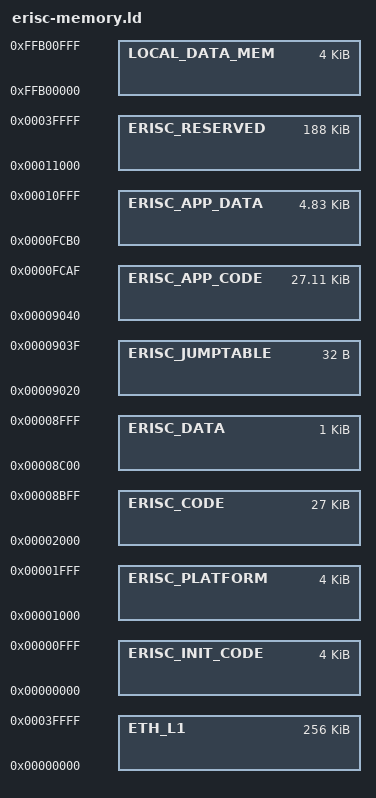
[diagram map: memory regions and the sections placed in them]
MEMORY
{
    LOCAL_DATA_MEM : ORIGIN = 0xFFB00000, LENGTH = 4K
    ETH_L1 : ORIGIN = 0x00000000, LENGTH = 256K
    ERISC_INIT_CODE : ORIGIN = 0x00000000, LENGTH = 4K
    ERISC_PLATFORM : ORIGIN = 0x00001000, LENGTH = 4K
    ERISC_CODE : ORIGIN = 0x00002000, LENGTH = 27K
    ERISC_DATA : ORIGIN = 0x00008C00, LENGTH = 1K
    ERISC_JUMPTABLE : ORIGIN = 0x00009020, LENGTH = 32
    ERISC_APP_CODE : ORIGIN = 0x00009040, LENGTH = 26K - 64 + 1200
    ERISC_APP_DATA : ORIGIN = 0x0000FCB0, LENGTH = 6K - 1200
    ERISC_RESERVED : ORIGIN = 0x11000, LENGTH = 188K
}
